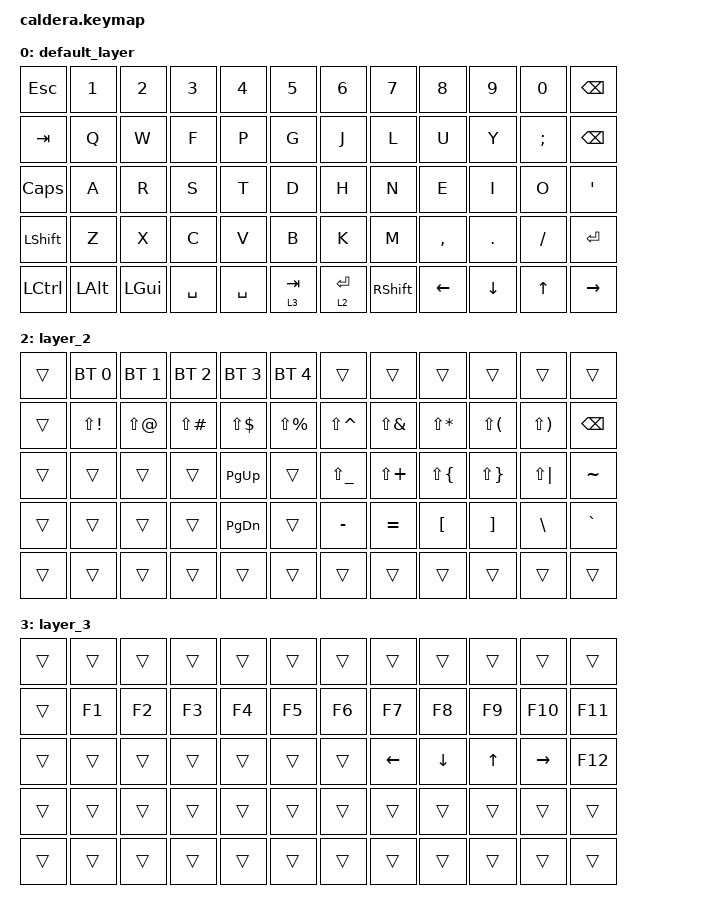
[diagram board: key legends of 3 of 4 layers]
#include <behaviors.dtsi>
#include <dt-bindings/zmk/bt.h>
#include <dt-bindings/zmk/keys.h>

/ {
    keymap {
        compatible = "zmk,keymap";

        default_layer {
            // ---------------------------------------------------------------------------------
            // |   `  |  1  |  2  |  3  |  4  |  5  |     |  6  |  7  |  8  |  9  |  0  | BKSP |
            // |  TAB |  Q  |  W  |  E  |  R  |  T  |     |  Y  |  U  |  I  |  O  |  P  |  \   |
            // | CAPS |  A  |  S  |  D  |  F  |  G  |     |  H  |  J  |  K  |  L  |  ;  |  ENT |
            // | SHFT |  Z  |  X  |  C  |  V  |  B  |     |  N  |  M  |  ,  |  .  |  /  | APOS |
            // | CTRL | ALT | GUI | SPC | SPC | SPC |     | SPC | LOW |LARW |DARW |UARW | RARW |

            bindings = <
&kp ESCAPE  &kp N1    &kp N2    &kp N3     &kp N4     &kp N5       &kp N6       &kp N7           &kp N8          &kp N9          &kp N0         &kp BSPC
&kp TAB     &kp Q     &kp W     &kp F      &kp P      &kp G        &kp J        &kp L            &kp U           &kp Y           &kp SEMICOLON  &kp BACKSPACE
&kp CAPS    &kp A     &kp R     &kp S      &kp T      &kp D        &kp H        &kp N            &kp E           &kp I           &kp O          &kp SQT
&kp LSHFT   &kp Z     &kp X     &kp C      &kp V      &kp B        &kp K        &kp M            &kp COMMA       &kp DOT         &kp FSLH       &kp ENTER
&kp LCTRL   &kp LALT  &kp LGUI  &kp SPACE  &kp SPACE  &lt 3 TAB    &lt 2 ENTER  &kp RIGHT_SHIFT  &kp LEFT_ARROW  &kp DOWN_ARROW  &kp UP_ARROW   &kp RIGHT_ARROW
            >;
        };

        lower_layer {
            // ------------------------------------------------------------------------------------------------------------
            // |       |  BT1  |  BT2  |  BT3  |  BT4  |  BT5  |          |       |       |       |       |       | BTCLR |
            // |       |       |       |       |       |       |          |       |       |       |       |       |       |
            // |       |       |       | LPAR  | RPAR  |       |          |       | LBKT  | RBKT  |       |       |       |
            // |       |       |       |       |       |       |          |       |       |       |       |       |       |

            bindings = <
&trans  &bt BT_SEL 0  &bt BT_SEL 1  &bt BT_SEL 2  &bt BT_SEL 3  &bt BT_SEL 4    &trans  &trans    &trans    &trans     &trans     &bt BT_CLR
&trans  &trans        &trans        &trans        &trans        &trans          &trans  &trans    &trans    &trans     &trans     &trans
&trans  &trans        &trans        &kp LPAR      &kp RPAR      &trans          &trans  &kp LBKT  &kp RBKT  &kp MINUS  &kp EQUAL  &trans
&trans  &trans        &trans        &trans        &trans        &trans          &trans  &trans    &trans    &trans     &trans     &trans
            >;
        };

        layer_2 {
            bindings = <
&trans  &bt BT_SEL 0  &bt BT_SEL 1  &bt BT_SEL 2   &bt BT_SEL 3  &bt BT_SEL 4     &trans         &trans        &trans        &trans        &trans        &trans
&trans  &kp LS(EXCL)  &kp LS(AT)    &kp LS(POUND)  &kp LS(DLLR)  &kp LS(PRCNT)    &kp LS(CARET)  &kp LS(AMPS)  &kp LS(STAR)  &kp LS(LPAR)  &kp LS(RPAR)  &kp BSPC
&trans  &trans        &trans        &trans         &kp PG_UP     &trans           &kp LS(UNDER)  &kp LS(PLUS)  &kp LS(LBRC)  &kp LS(RBRC)  &kp LS(PIPE)  &kp TILDE
&trans  &trans        &trans        &trans         &kp PG_DN     &trans           &kp MINUS      &kp EQUAL     &kp LBKT      &kp RBKT      &kp BSLH      &kp GRAVE
&trans  &trans        &trans        &trans         &trans        &trans           &trans         &trans        &trans        &trans        &trans        &trans
            >;
        };

        layer_3 {
            bindings = <
&trans  &trans  &trans  &trans  &trans  &trans    &trans  &trans    &trans    &trans  &trans     &trans
&trans  &kp F1  &kp F2  &kp F3  &kp F4  &kp F5    &kp F6  &kp F7    &kp F8    &kp F9  &kp F10    &kp F11
&trans  &trans  &trans  &trans  &trans  &trans    &trans  &kp LEFT  &kp DOWN  &kp UP  &kp RIGHT  &kp F12
&trans  &trans  &trans  &trans  &trans  &trans    &trans  &trans    &trans    &trans  &trans     &trans
&trans  &trans  &trans  &trans  &trans  &trans    &trans  &trans    &trans    &trans  &trans     &trans
            >;
        };
    };
};
